# FM33LC0XX register map
File version: 1.0
CPU: Cortex-M0 r1p0, little endian, no MPU, no FPU, 3 interrupt priority bits
Registers are 32-bit, read-write, reset 0x0 unless marked. A register's access mark holds for its fields unless they carry their own. Offsets are from the block's base; [hi:lo] are bit positions.

## UART — UART module information
Base 0x40019C00
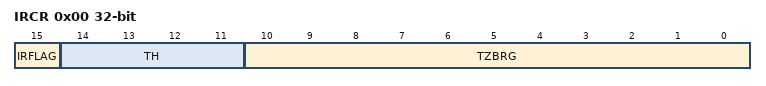
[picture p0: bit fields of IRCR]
0x00 IRCR — Infrared modulation Control Register
  [15] IRFLAG — IRFLAG field description
  [14:11] TH — TH field description
  [10:0] TZBRG — TZBRG field description

## UART0 — UART0 module information
Base 0x40011C00
Same registers: UART1 0x40012000
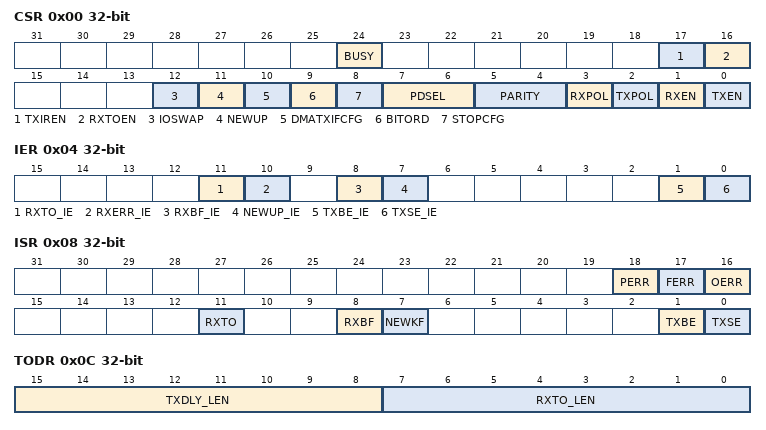
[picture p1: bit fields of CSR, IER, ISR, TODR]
0x00 CSR access per field — UART0 Control Status Register
  [24] BUSY ro — BUSY field description
  [17] TXIREN rw — TXIREN field description
  [16] RXTOEN rw — RXTOEN field description
  [12] IOSWAP rw — IOSWAP field description
  [11] NEWUP rw — NEWUP field description
  [10] DMATXIFCFG rw — DMATXIFCFG field description
  [9] BITORD rw — BITORD field description
  [8] STOPCFG rw — STOPCFG field description
  [7:6] PDSEL rw — PDSEL field description
  [5:4] PARITY rw — PARITY field description
  [3] RXPOL rw — RXPOL field description
  [2] TXPOL rw — TXPOL field description
  [1] RXEN rw — RXEN field description
  [0] TXEN rw — TXEN field description
0x04 IER — UART0 Interrupt Enable Register
  [11] RXTO_IE — RXTO_IE field description
  [10] RXERR_IE — RXERR_IE field description
  [8] RXBF_IE — RXBF_IE field description
  [7] NEWUP_IE — NEWUP_IE field description
  [1] TXBE_IE — TXBE_IE field description
  [0] TXSE_IE — TXSE_IE field description
0x08 ISR access per field — UART0 Interrupt Status Register
  [18] PERR rw — PERR field description
  [17] FERR rw — FERR field description
  [16] OERR rw — OERR field description
  [11] RXTO rw — RXTO field description
  [8] RXBF rw — RXBF field description
  [7] NEWKF rw — NEWKF field description
  [1] TXBE ro — TXBE field description
  [0] TXSE rw — TXSE field description
0x0C TODR — UART0 Time-Out and Delay Register
  [15:8] TXDLY_LEN — TXDLY_LEN field description
  [7:0] RXTO_LEN — RXTO_LEN field description
0x10 RXBUF ro — UART0 Receive Buffer
  [8:0] RXBUF — RXBUF field description
0x14 TXBUF — UART0 Transmit Buffer
  [8:0] TXBUF — TXBUF field description
0x18 BGR — UART0 Baud rate Generator Register
  [15:0] SPBRG — SPBRG field description

## UART4 — UART4 module information
Base 0x4001A000
Same registers: UART5 0x4001A400
Registers as UART0 (with UART0 read as UART4), without TODR.

## LPUART0 — LPUART0 module information
Base 0x40010400
Same registers: LPUART1 0x40018400
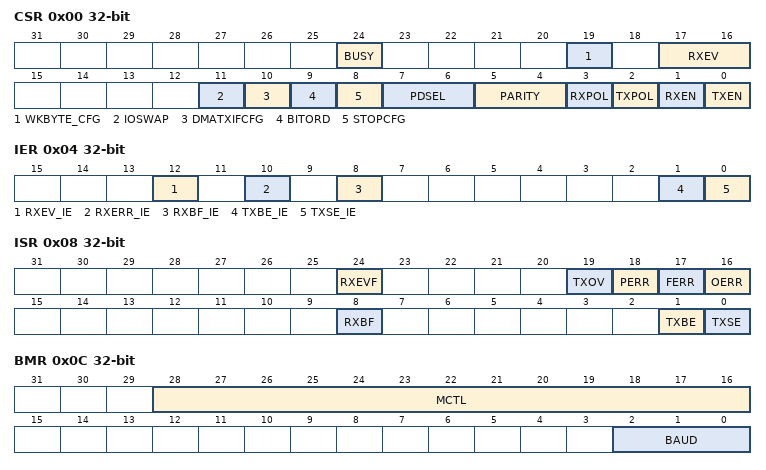
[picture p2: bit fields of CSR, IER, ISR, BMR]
0x00 CSR access per field — LPUART0 Control Status Register
  [24] BUSY ro — BUSY field description
  [19] WKBYTE_CFG rw — WKBYTE_CFG field description
  [17:16] RXEV rw — RXEV field description
  [11] IOSWAP rw — IOSWAP field description
  [10] DMATXIFCFG rw — DMATXIFCFG field description
  [9] BITORD rw — BITORD field description
  [8] STOPCFG rw — STOPCFG field description
  [7:6] PDSEL rw — PDSEL field description
  [5:4] PARITY rw — PARITY field description
  [3] RXPOL rw — RXPOL field description
  [2] TXPOL rw — TXPOL field description
  [1] RXEN rw — RXEN field description
  [0] TXEN rw — TXEN field description
0x04 IER — LPUART0 Interrupt Enable Register
  [12] RXEV_IE — RXEV_IE field description
  [10] RXERR_IE — RXERR_IE field description
  [8] RXBF_IE — RXBF_IE field description
  [1] TXBE_IE — TXBE_IE field description
  [0] TXSE_IE — TXSE_IE field description
0x08 ISR — LPUART0 Interrupt Status Register
  [24] RXEVF — RXEVF field description
  [19] TXOV — TXOV field description
  [18] PERR — PERR field description
  [17] FERR — FERR field description
  [16] OERR — OERR field description
  [8] RXBF — RXBF field description
  [1] TXBE — TXBE field description
  [0] TXSE — TXSE field description
0x0C BMR — LPUART0 Baud rate Modulation Register
  [28:16] MCTL — MCTL field description
  [2:0] BAUD — BAUD field description
0x10 RXBUF ro — LPUART0 Receive Buffer Register
  [8:0] RXBUF — RXBUF field description
0x14 TXBUF — LPUART0 Transmit Buffer Register
  [8:0] TXBUF — TXBUF field description
0x18 DMR — LPUART0 data Matching Register
  [8:0] MATD — MATD field description
